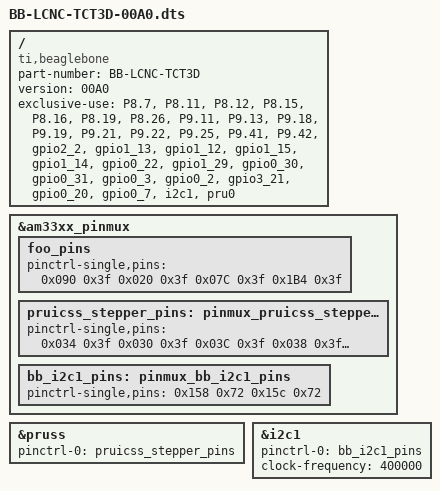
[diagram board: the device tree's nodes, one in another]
/dts-v1/;
/plugin/;

/ {
	compatible = "ti,beaglebone", "ti,beaglebone-black";

	/* identification */
	part-number = "BB-LCNC-TCT3D";
	version = "00A0";

	/* state the resources this cape uses */
	exclusive-use =
		/* the pin header P8 uses */
		"P8.7",		/* gpio2.2	Machine_Pwr */
		"P8.11",	/* gpio1.13	X_Dir */
		"P8.12",	/* gpio1.12	X_Step */
		"P8.15",	/* gpio1.15	Y_Dir */
		"P8.16",	/* gpio1.14	Y_Step */
		"P8.19",	/* gpio0.22	Estop_Sw */
		"P8.26",	/* gpio1.29	Status */
		/* the pin header P9 uses */
		"P9.11",	/* gpio0.30	B_Step */
		"P9.13",	/* gpio0.31	Z_Step */
		"P9.18",	/* i2c1_sda */
		"P9.19",	/* i2c1_scl */
		"P9.21",	/* gpio0.3	A_Dir */
		"P9.22",	/* gpio0.2	A_Step */
		"P9.25",	/* gpio3.21	Z_Dir */
		"P9.41",	/* gpio0.20	Estop_Ext */
		"P9.42",	/* gpio0.7	B_Dir */

		/* the hardware IP uses */
		"gpio2_2",
		"gpio1_13",
		"gpio1_12",
		"gpio1_15",
		"gpio1_14",
		"gpio0_22",
		"gpio1_29",
		"gpio0_30",
		"gpio0_31",
		"gpio0_3",
		"gpio0_2",
		"gpio3_21",
		"gpio0_20",
		"gpio0_7",
		"i2c1",
		"pru0";

	fragment@0 {
		target = <&am33xx_pinmux>;
		__overlay__ {

			foo_pins: foo_pins {
				pinctrl-single,pins = <
					0x090 0x3f	/* P8.7		gpio2.2		Machine_Pwr	*/
					0x020 0x3f	/* P8.19	gpio0.22	Estop_Sw	*/
					0x07C 0x3f	/* P8.26	gpio1.29	Status		*/
					0x1B4 0x3f	/* P9.41	gpio0.20	Estop_Ext	*/
				>;
			};

			pruicss_stepper_pins: pinmux_pruicss_stepper_pins{
				pinctrl-single,pins = <
					0x034 0x3f	/* P8.11	gpio1.13	X_Dir		*/
					0x030 0x3f	/* P8.12	gpio1.12	X_Step		*/
					0x03C 0x3f	/* P8.15	gpio1.15	Y_Dir		*/
					0x038 0x3f	/* P8.16	gpio1.14	Y_Step		*/
					0x1AC 0x3f	/* P9.25	gpio3.21	Z_Dir		*/
					0x074 0x3f	/* P9.13	gpio0.31	Z_Step		*/
					0x154 0x3f	/* P9.21	gpio0.3		A_Dir		*/
					0x150 0x3f	/* P9.22	gpio0.2		A_Step		*/
					0x164 0x3f	/* P9.42	gpio0.7		B_Dir		*/
					0x070 0x3f	/* P9.11	gpio0.30	B_Step		*/
				>;
			};

			bb_i2c1_pins: pinmux_bb_i2c1_pins {
				pinctrl-single,pins = <
					0x158 0x72	/* spi0_d1.i2c1_sda, SLEWCTRL_SLOW | INPUT_PULLUP | MODE2 */
					0x15c 0x72	/* spi0_cs0.i2c1_scl, SLEWCTRL_SLOW | INPUT_PULLUP | MODE2 */
				>;
			};
		};
	};

	fragment@1 {
		target = <&pruss>;
		__overlay__ {
			status = "okay";
			pinctrl-names = "default";
			pinctrl-0 = <&pruicss_stepper_pins>;
		};
	};

	fragment@2 {
		target = <&i2c1>;	/* i2c1 is numbered correctly */
		__overlay__ {
			status = "okay";
			pinctrl-names = "default";
			pinctrl-0 = <&bb_i2c1_pins>;

			/* this is the configuration part */
			clock-frequency = <400000>;	

			#address-cells = <1>;
			#size-cells = <0>;

			/* add any i2c devices on the bus here */

			// commented out example of a touchscreen (taken from BB-BONE-LCD7-01-00A4) */
			// maxtouch@4a {
			//	compatible = "mXT224";
			//	reg = <0x4a>;
			//	interrupt-parent = <&gpio4>;
			//	interrupts = <19 0x0>;
			//	atmel,irq-gpio = <&gpio4 19 0>;
			// };
		};
	};
};

